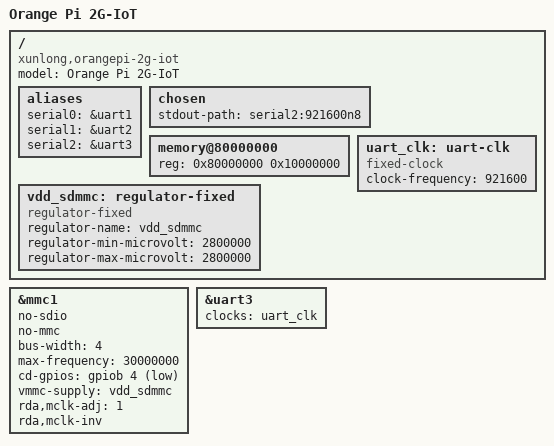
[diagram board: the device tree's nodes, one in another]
// SPDX-License-Identifier: (GPL-2.0+ OR MIT)
/*
 * Copyright (c) 2017 Andreas Färber
 * Copyright (c) 2018 Manivannan Sadhasivam
 */

/dts-v1/;

#include <dt-bindings/gpio/gpio.h>
#include "rda8810pl.dtsi"

/ {
	compatible = "xunlong,orangepi-2g-iot", "rda,8810pl";
	model = "Orange Pi 2G-IoT";

	aliases {
		serial0 = &uart1;
		serial1 = &uart2;
		serial2 = &uart3;
	};

	chosen {
		stdout-path = "serial2:921600n8";
	};

	memory@80000000 {
		device_type = "memory";
		reg = <0x80000000 0x10000000>;
	};

	vdd_sdmmc: regulator-fixed {
		compatible = "regulator-fixed";
		regulator-name = "vdd_sdmmc";
		regulator-min-microvolt = <2800000>;
		regulator-max-microvolt = <2800000>;
	};

	uart_clk: uart-clk {
		compatible = "fixed-clock";
		clock-frequency = <921600>;
		#clock-cells = <0>;
	};
};

&mmc1 {
	status = "okay";
	no-sdio;
	no-mmc;
	bus-width = <4>;
	max-frequency = <30000000>;
	cd-gpios = <&gpiob 4 GPIO_ACTIVE_LOW>;
	vmmc-supply = <&vdd_sdmmc>;
	rda,mclk-adj = /bits/ 8 <1>;
	rda,mclk-inv;
};

&uart3 {
	status = "okay";
	clocks = <&uart_clk>;
};
